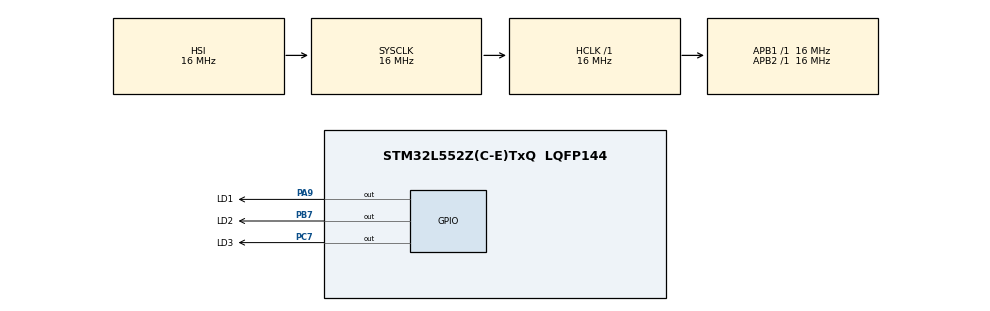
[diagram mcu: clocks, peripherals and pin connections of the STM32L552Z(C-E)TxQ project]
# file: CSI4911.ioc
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FREERTOS.Tasks01=defaultTask,24,512,StartDefaultTask,Default,NULL,Dynamic,NULL,NULL;task_green,8,512,StartTask02,Default,NULL,Dynamic,NULL,NULL;task_blue,24,512,StartTask03,Default,NULL,Dynamic,NULL,NULL;task_red,40,512,StartTask04,Default,NULL,Dynamic,NULL,NULL
FREERTOS.configMINIMAL_STACK_SIZE=512
FREERTOS.configTOTAL_HEAP_SIZE=32768
FREERTOS.configUSE_NEWLIB_REENTRANT=1
Mcu.Family=STM32L5
Mcu.Name=STM32L552Z(C-E)TxQ
Mcu.Package=LQFP144
NVIC.PriorityGroup=NVIC_PRIORITYGROUP_3
NVIC.TIM6_IRQn=true\:7\:0\:false\:false\:true\:false\:false\:true\:true
NVIC.TimeBase=TIM6_IRQn
NVIC.TimeBaseIP=TIM6
PA9.GPIO_Label=LD1
PA9.Signal=GPIO_Output
PB7.GPIO_Label=LD2
PB7.Signal=GPIO_Output
PC7.GPIO_Label=LD3
PC7.Signal=GPIO_Output
ProjectManager.HeapSize=0x200
ProjectManager.StackSize=0x400
ProjectManager.TargetToolchain=STM32CubeIDE
RCC.AHBFreq_Value=16000000
RCC.APB1Freq_Value=16000000
RCC.APB1TimFreq_Value=16000000
RCC.APB2Freq_Value=16000000
RCC.APB2TimFreq_Value=16000000
RCC.CortexFreq_Value=16000000
RCC.HCLKFreq_Value=16000000
RCC.HSE_VALUE=16000000
RCC.HSI48_VALUE=48000000
RCC.HSI_VALUE=16000000
RCC.LSE_VALUE=32768
RCC.MSI_VALUE=4000000
RCC.SYSCLKFreq_VALUE=16000000
RCC.SYSCLKSource=RCC_SYSCLKSOURCE_HSI
RCC.VCOOutputFreq_Value=32000000
VP_FREERTOS_VS_CMSIS_V2.Mode=CMSIS_V2
VP_ICACHE_VS_ICACHE.Mode=DefaultMode
VP_PWR_VS_DBSignals.Mode=DisableDeadBatterySignals
VP_PWR_VS_SECSignals.Mode=Security/Privilege
VP_SYS_VS_tim6.Mode=TIM6
board=custom

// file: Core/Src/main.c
/* USER CODE BEGIN Header */
/**
  ******************************************************************************
  * @file           : main.c
  * @brief          : Main program body
  ******************************************************************************
  * @attention
  *
  * Copyright (c) 2026 STMicroelectronics.
  * All rights reserved.
  *
  * This software is licensed under terms that can be found in the LICENSE file
  * in the root directory of this software component.
  * If no LICENSE file comes with this software, it is provided AS-IS.
  *
  ******************************************************************************
  */
/* USER CODE END Header */
#include "main.h"
#include "cmsis_os.h"

void SystemClock_Config(void);
static void MX_GPIO_Init(void);
static void MX_ICACHE_Init(void);
void MX_FREERTOS_Init(void);

int main(void)
{

  /* MCU Configuration--------------------------------------------------------*/

  /* Reset of all peripherals, Initializes the Flash interface and the Systick. */
  HAL_Init();

  /* Configure the system clock */
  SystemClock_Config();

  /* Initialize all configured peripherals */
  MX_GPIO_Init();
  MX_ICACHE_Init();

  /* Init scheduler */
  osKernelInitialize();

  MX_FREERTOS_Init();

  /* Start scheduler */
  osKernelStart();

  /* We should never get here as control is now taken by the scheduler */

  /* Infinite loop */
  while (1)
  {

  }
}

void SystemClock_Config(void)
{
  RCC_OscInitTypeDef RCC_OscInitStruct = {0};
  RCC_ClkInitTypeDef RCC_ClkInitStruct = {0};

  /** Configure the main internal regulator output voltage
  */
  if (HAL_PWREx_ControlVoltageScaling(PWR_REGULATOR_VOLTAGE_SCALE2) != HAL_OK)
  {
    Error_Handler();
  }

  /** Initializes the RCC Oscillators according to the specified parameters
  * in the RCC_OscInitTypeDef structure.
  */
  RCC_OscInitStruct.OscillatorType = RCC_OSCILLATORTYPE_HSI;
  RCC_OscInitStruct.HSIState = RCC_HSI_ON;
  RCC_OscInitStruct.HSICalibrationValue = RCC_HSICALIBRATION_DEFAULT;
  RCC_OscInitStruct.PLL.PLLState = RCC_PLL_NONE;
  if (HAL_RCC_OscConfig(&RCC_OscInitStruct) != HAL_OK)
  {
    Error_Handler();
  }

  /** Initializes the CPU, AHB and APB buses clocks
  */
  RCC_ClkInitStruct.ClockType = RCC_CLOCKTYPE_HCLK|RCC_CLOCKTYPE_SYSCLK
                              |RCC_CLOCKTYPE_PCLK1|RCC_CLOCKTYPE_PCLK2;
  RCC_ClkInitStruct.SYSCLKSource = RCC_SYSCLKSOURCE_HSI;
  RCC_ClkInitStruct.AHBCLKDivider = RCC_SYSCLK_DIV1;
  RCC_ClkInitStruct.APB1CLKDivider = RCC_HCLK_DIV1;
  RCC_ClkInitStruct.APB2CLKDivider = RCC_HCLK_DIV1;

  if (HAL_RCC_ClockConfig(&RCC_ClkInitStruct, FLASH_LATENCY_1) != HAL_OK)
  {
    Error_Handler();
  }
}

static void MX_ICACHE_Init(void)
{

  /** Enable instruction cache (default 2-ways set associative cache)
  */
  if (HAL_ICACHE_Enable() != HAL_OK)
  {
    Error_Handler();
  }

}

static void MX_GPIO_Init(void)
{
  GPIO_InitTypeDef GPIO_InitStruct = {0};

  /* GPIO Ports Clock Enable */
  __HAL_RCC_GPIOC_CLK_ENABLE();
  __HAL_RCC_GPIOA_CLK_ENABLE();
  __HAL_RCC_GPIOB_CLK_ENABLE();

  /*Configure GPIO pin Output Level */
  HAL_GPIO_WritePin(LD3_GPIO_Port, LD3_Pin, GPIO_PIN_RESET);

  /*Configure GPIO pin Output Level */
  HAL_GPIO_WritePin(LD1_GPIO_Port, LD1_Pin, GPIO_PIN_RESET);

  /*Configure GPIO pin Output Level */
  HAL_GPIO_WritePin(LD2_GPIO_Port, LD2_Pin, GPIO_PIN_RESET);

  /*Configure GPIO pin : LD3_Pin */
  GPIO_InitStruct.Pin = LD3_Pin;
  GPIO_InitStruct.Mode = GPIO_MODE_OUTPUT_PP;
  GPIO_InitStruct.Pull = GPIO_NOPULL;
  GPIO_InitStruct.Speed = GPIO_SPEED_FREQ_LOW;
  HAL_GPIO_Init(LD3_GPIO_Port, &GPIO_InitStruct);

  /*Configure GPIO pin : LD1_Pin */
  GPIO_InitStruct.Pin = LD1_Pin;
  GPIO_InitStruct.Mode = GPIO_MODE_OUTPUT_PP;
  GPIO_InitStruct.Pull = GPIO_NOPULL;
  GPIO_InitStruct.Speed = GPIO_SPEED_FREQ_LOW;
  HAL_GPIO_Init(LD1_GPIO_Port, &GPIO_InitStruct);

  /*Configure GPIO pin : LD2_Pin */
  GPIO_InitStruct.Pin = LD2_Pin;
  GPIO_InitStruct.Mode = GPIO_MODE_OUTPUT_PP;
  GPIO_InitStruct.Pull = GPIO_NOPULL;
  GPIO_InitStruct.Speed = GPIO_SPEED_FREQ_LOW;
  HAL_GPIO_Init(LD2_GPIO_Port, &GPIO_InitStruct);

}

void HAL_TIM_PeriodElapsedCallback(TIM_HandleTypeDef *htim)
{
  if (htim->Instance == TIM6)
  {
    HAL_IncTick();
  }
}

void Error_Handler(void)
{
  __disable_irq();
  while (1)
  {
  }
}

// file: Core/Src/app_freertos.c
/* USER CODE BEGIN Header */
/**
  ******************************************************************************
  * File Name          : freertos.c
  * Description        : Code for freertos applications
  ******************************************************************************
  * @attention
  *
  * Copyright (c) 2026 STMicroelectronics.
  * All rights reserved.
  *
  * This software is licensed under terms that can be found in the LICENSE file
  * in the root directory of this software component.
  * If no LICENSE file comes with this software, it is provided AS-IS.
  *
  ******************************************************************************
  */
/* USER CODE END Header */

#include "FreeRTOS.h"
#include "task.h"
#include "main.h"
#include "trace_buffer.h"
#include "trace_transport.h"

/* USER CODE BEGIN Application */
#include "cmsis_os.h" // Required for CMSIS-RTOS v2 API

/* Task function prototypes */
void StartTask_Sensor(void *argument);
void StartTask_Control(void *argument);
void StartTask_Logger(void *argument);
void StartTask_Communication(void *argument);

const osThreadAttr_t sensorTask_attributes = {
  .name = "SensorTask",
  .stack_size = 512 * 4, // Changed from 128 to 512
  .priority = (osPriority_t) osPriorityLow,
};
const osThreadAttr_t controlTask_attributes = {
  .name = "ControlTask",
  .stack_size = 512 * 4, // Changed from 128 to 512
  .priority = (osPriority_t) osPriorityNormal,
};
const osThreadAttr_t loggerTask_attributes = {
  .name = "LoggerTask",
  .stack_size = 512 * 4, // Changed from 128 to 512
  .priority = (osPriority_t) osPriorityHigh,
};
const osThreadAttr_t communicationTask_attributes = {
  .name = "CommunicationTask",
  .stack_size = 512 * 4,
  .priority = (osPriority_t) osPriorityNormal,
};

volatile uint32_t sensorReleaseCount;
volatile uint32_t controlReleaseCount;
volatile uint32_t loggerReleaseCount;
volatile uint32_t communicationReleaseCount;

static void RunPeriodicTask(volatile uint32_t *releaseCount,
                            uint32_t period,
                            GPIO_TypeDef *gpioPort,
                            uint16_t gpioPin)
{
  uint32_t nextRelease = osKernelGetTickCount();

  for (;;)
  {
    nextRelease += period;
    (*releaseCount)++;
    HAL_GPIO_TogglePin(gpioPort, gpioPin);
    osDelayUntil(nextRelease);
  }
}

/* This function is called automatically by main.c before the scheduler starts */
void MX_FREERTOS_Init(void) {
  Trace_Init();
  TraceTransport_Init();
  osThreadNew(StartTask_Sensor, NULL, &sensorTask_attributes);
  osThreadNew(StartTask_Control, NULL, &controlTask_attributes);
  osThreadNew(StartTask_Logger, NULL, &loggerTask_attributes);
  osThreadNew(StartTask_Communication, NULL, &communicationTask_attributes);
}

void StartTask_Sensor(void *argument)
{
  (void)argument;
  RunPeriodicTask(&sensorReleaseCount, 100U, LD1_GPIO_Port, LD1_Pin);
}

void StartTask_Control(void *argument)
{
  (void)argument;
  RunPeriodicTask(&controlReleaseCount, 250U, LD2_GPIO_Port, LD2_Pin);
}

void StartTask_Logger(void *argument)
{
  (void)argument;
  RunPeriodicTask(&loggerReleaseCount, 500U, LD3_GPIO_Port, LD3_Pin);
}

void StartTask_Communication(void *argument)
{
  uint32_t nextRelease = osKernelGetTickCount();

  (void)argument;
  for (;;)
  {
    nextRelease += 10U;
    communicationReleaseCount++;
    TraceTransport_SendPending();
    osDelayUntil(nextRelease);
  }
}

/* USER CODE END Application */
